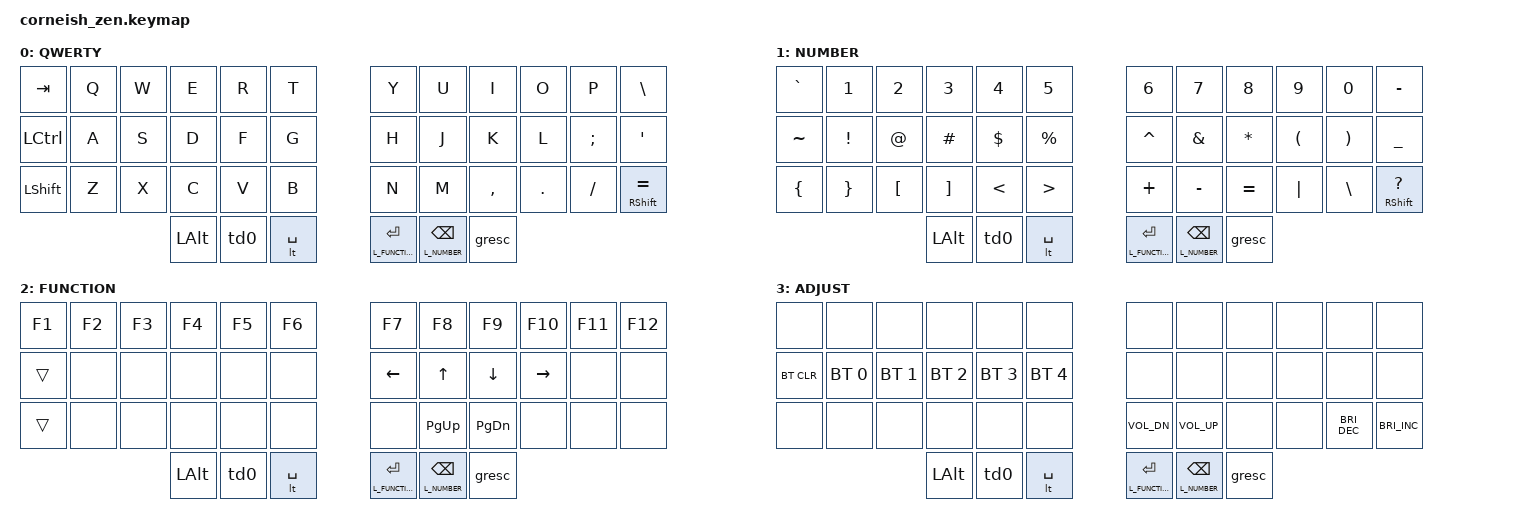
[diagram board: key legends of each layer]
#include <behaviors.dtsi>
#include <dt-bindings/zmk/keys.h>
#include <dt-bindings/zmk/bt.h>

#define L_DEFAULT 0 // QWERTY is the default layout
#define L_NUMBER 1
#define L_FUNCTION 2
#define L_ADJUST 3

#define COMBO(NAME, KEYPOS) \
  combo_##NAME { \
    timeout-ms = <40>; \
    key-positions = <KEYPOS>; \
    bindings = <&kp NAME>; \
  };

/ {
  chosen {
    zmk,matrix_transform = &default_transform;
  };
};

/ {
  macros {
    gui_and_space: gui_and_space {
      label = "ZM_gui_and_space";
      compatible = "zmk,behavior-macro";
      #binding-cells = <0>;
      wait-ms = <1>;
      bindings = <&macro_press &kp LGUI>,
        <&macro_tap &kp SPACE>,
        <&macro_release &kp LGUI>;
    };

    k_lock: k_lock {
      label = "ZM_k_lock";
      compatible = "zmk,behavior-macro";
      #binding-cells = <0>;
      wait-ms = <1>;
      bindings = <&macro_press &kp LGUI>,
        <&macro_press &kp LCTRL>,
        <&macro_tap &kp Q>,
        <&macro_release &kp LCTRL>,
        <&macro_release &kp LGUI>;
      };
  };

  behaviors {
    td0: tap_dance_0 {
      compatible = "zmk,behavior-tap-dance";
      label = "TAP_DANCE_0";
      #binding-cells = <0>;
      tapping-term-ms = <200>;
      bindings = <&kp LGUI>, <&gui_and_space>;
    };           
  };

  conditional_layers {
    compatible = "zmk,conditional-layers";                        
    tri_layer {
      if-layers = <L_NUMBER L_FUNCTION>;
      then-layer = <L_ADJUST>;                        
    };
  };

  combos {
    compatible = "zmk,combos";
    
    // Left-hand combos
    COMBO(ESC, 0 1)
  };

  keymap {
    compatible = "zmk,keymap";

    default_layer {
      label = "QWERTY";
// --------------------------------------------------------------------------------------
// |  Tab  |  Q  |  W  |  E  |  R  |  T  |   |  Y  |  U   |  I  |  O  |  P  |     \     |
// | CTRL  |  A  |  S  |  D  |  F  |  G  |   |  H  |  J   |  K  |  L  |  ;  |     '     |
// | SHIFT |  Z  |  X  |  C  |  V  |  B  |   |  N  |  M   |  ,  |  .  |  /  |  =/SHIFT  |
//                     | ALT | GUI | SPC |   | ENT/FUNC | BSPC/SHIFT | ESC/` |
        bindings = <
  &kp TAB    &kp Q &kp W &kp E &kp R &kp T    &kp Y &kp U  &kp I     &kp O   &kp P    &kp BSLH
  &kp LCTRL  &kp A &kp S &kp D &kp F &kp G    &kp H &kp J  &kp K     &kp L   &kp SEMI &kp SQT
  &kp LSHIFT &kp Z &kp X &kp C &kp V &kp B    &kp N &kp M  &kp COMMA &kp DOT &kp FSLH &mt RIGHT_SHIFT EQUAL
                   &kp LALT &td0 &lt SPACE    &lt L_FUNCTION RET &lt L_NUMBER BSPC &gresc
      >;
    };

    number_layer {
      label = "NUMBER";
// -----------------------------------------------------------------------------------
// |  `  |  1  |  2  |  3  |  4  |  5  |   |  6  |  7  |  8  |  9  |  0  |     -     |
// |  ~  |  !  |  @  |  #  |  $  |  %  |   |  ^  |  &  |  *  |  (  |  )  |     _     |
// |  {  |  }  |  [  |  ]  |  <  |  >  |   |  +  |  -  |  =  |  |  |  \  |  ?/SHIFT  |
//                   | ALT | GUI | SPC |   | ENT/FUNC | BSPC/NUMB | Esc/` |
      bindings = <
  &kp GRAVE   &kp N1          &kp N2      &kp N3      &kp N4       &kp N5        &kp N6     &kp N7     &kp N8     &kp N9    &kp N0    &kp MINUS
  &kp TILDE   &kp EXCLAMATION &kp AT_SIGN &kp HASH    &kp DOLLAR   &kp PERCENT   &kp CARET  &kp AMPS   &kp STAR   &kp LPAR  &kp RPAR  &kp UNDERSCORE
  &kp LBRC    &kp RBRC        &kp LBKT    &kp RBKT    &kp LT       &kp GT        &kp PLUS   &kp MINUS  &kp EQUAL  &kp PIPE  &kp BSLH  &mt RIGHT_SHIFT QMARK
                                        &kp LALT &td0 &lt SPACE    &lt L_FUNCTION RET &lt L_NUMBER BSPC &gresc
      >;
    };

    symbol_layer {
      label = "FUNCTION";
// --------------------------------------------------------------------
// | F1 | F2 | F3 | F4 | F5 | F6 |   | F7 | F8 | F9 | F10 | F11 | F12 |
// |    |    |    |    |    |    |   | <  |  ^ |  v |  >  |     |     |
// |    |    |    |    |    |    |   |    |    |    |     |     |     |
//             | ALT | GUI | SPC |   | ENT/FUNC | BSPC/NUMB | Esc/` |
      bindings = <
  &kp F1 &kp F2 &kp F3 &kp F4 &kp F5 &kp F6   &kp F7   &kp F8      &kp F9         &kp F10   &kp F11 &kp F12
  &trans &none  &none  &none  &none  &none    &kp LEFT &kp UP      &kp DOWN       &kp RIGHT &none   &none
  &trans &none  &none  &none  &none  &none    &none    &kp PAGE_UP &kp PAGE_DOWN  &none     &none   &none
                    &kp LALT &td0 &lt SPACE   &lt L_FUNCTION RET &lt L_NUMBER BSPC &gresc
      >;
    };

    adjust_layer {
      label = "ADJUST";
// -------------------------------------------------------------------------------------------
// |  XXX  | XXX | XXX | XXX | XXX | XXX |   |  XXX  |  XXX  |  XXX  |  XXX  |  XXX  |  XXX  |
// | BTCLR | BT1 | BT2 | BT3 | BT4 | BT5 |   |  XXX  |  XXX  |  XXX  |  XXX  |  XXX  |  XXX  |
// |  XXX  | XXX | XXX | XXX | XXX | XXX |   |  Vol- |  Vol+ |  XXX  |  XXX  |  Bri- |  Bri+ |
//                     | ALT | GUI | SPC |   | ENT/FUNC | BSPC/NUMB | Esc/` |
      bindings = <
  &none       &none        &none        &none        &none        &none           &none         &none        &none &none &none          &none
  &bt BT_CLR  &bt BT_SEL 0 &bt BT_SEL 1 &bt BT_SEL 2 &bt BT_SEL 3 &bt BT_SEL 4    &none         &none        &none &none &none          &none
  &none       &none        &none        &none        &none        &none           &kp C_VOL_DN  &kp C_VOL_UP &none &none &kp C_BRI_DEC  &kp C_BRI_INC
                                                    &kp LALT &td0 &lt SPACE       &lt L_FUNCTION RET &lt L_NUMBER BSPC &gresc
      >;
    };
  };
};

/*
layout:
  ortho_layout:
    split: true
    rows: 3
    columns: 6
    thumbs: 3
layers:
  QWERTY:
    - ["Tab", "Q", "W", "E", "R", "T", "Y", "U", "I", "O", "P", "\\"]
    - ["Ctrl", "A", "S", "D", "F", "G", "H", "J", "K", "L", ";", "'" ]
    - ["Shift", "Z", "X", "C", "V", "B", "N", "M", ",", ".", "/", {h: "Shift", t: "="}]
    - ["Alt", "Gui", "Space", {h: "L_FUNCTION", t: "Enter"}, {h: "L_NUMBER", t: "Bspace"}, "Esc/`"]

  NUMBER:
    - ["`", "1", "2", "3", "4", "5", "6", "7", "8", "9", "0", "-"]
    - ["~", "!", "@", "#", "$", "%", "^", "&", "*", "(", ")", "_"]
    - ["{", "}", "[", "]", "<", ">", "+", "-", "=", "|", "\\", {h: "Shift", t: "?"}]
    - ["Alt", "Gui", "Space", {h: "L_FUNCTION", t: "Enter"}, {type: held, h: "L_NUMBER", t: "Bspace"}, "Esc/`"]

  FUNCTION:
    - ["F1", "F2", "F3", "F4", "F5", "F6", "F7", "F8", "F9", "F10", "F11", "F12"]
    - [null, null, null, null, null, null, "←", "↑", "↓", "→", null, null]
    - [null, null, null, null, null, null, null, pg_up, pg_down, null, null, null]
    - ["Alt", "Gui", "Space", {type: held, h: "L_FUNCTION", t: "Enter"}, {h: "L_NUMBER", t: "Bspace"}, "Esc/`"]

  ADJUST:
    - [null, null, null, null, null, null, null, null, null, null, null, null]
    - ["BT CLR", "BT 1", "BT 2", "BT 3", "BT 4", "BT 5", null, null, null, null, null, null]
    - [null, null, null, null, null, null, "Vol-", "Vol+", null, null, "Bri-", "Bri+"]
    - ["Alt", "Gui", "Space", {type: held, h: "L_FUNCTION", t: "Enter"}, {type: held, h: "L_NUMBER", t: "Bspace"}, "Esc/`"]
combos:
- {p: [0, 1], k: Esc, l: [QWERTY]}

for:
https://caksoylar-keymap-drawer-streamlitapp-2a0rau.streamlit.app
https://github.com/caksoylar/keymap-drawer
*/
